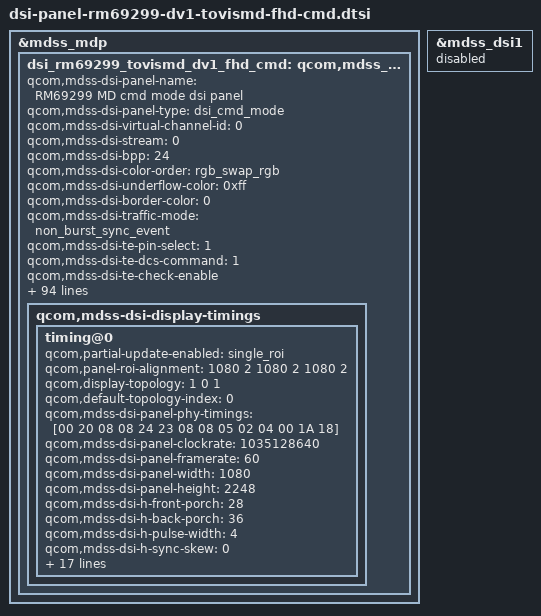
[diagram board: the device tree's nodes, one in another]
/* Copyright (c) 2014, Code Aurora Forum. All rights reserved.
 *
 * This program is free software; you can redistribute it and/or modify
 * it under the terms of the GNU General Public License version 2 and
 * only version 2 as published by the Free Software Foundation.
 *
 * This program is distributed in the hope that it will be useful,
 * but WITHOUT ANY WARRANTY; without even the implied warranty of
 * MERCHANTABILITY or FITNESS FOR A PARTICULAR PURPOSE.  See the
 * GNU General Public License for more details.
 */

&mdss_mdp {
    dsi_rm69299_tovismd_dv1_fhd_cmd: qcom,mdss_dsi_rm69299_tovismd_dv1_fhd_cmd {
		qcom,mdss-dsi-panel-name = "RM69299 MD cmd mode dsi panel";
		qcom,mdss-dsi-panel-type = "dsi_cmd_mode";
		qcom,mdss-dsi-virtual-channel-id = <0>;
		qcom,mdss-dsi-stream = <0>;
		qcom,mdss-dsi-bpp = <24>;
		qcom,mdss-dsi-color-order = "rgb_swap_rgb";
		qcom,mdss-dsi-underflow-color = <0xff>;
		qcom,mdss-dsi-border-color = <0>;
		qcom,mdss-dsi-traffic-mode = "non_burst_sync_event";
		qcom,mdss-dsi-te-pin-select = <1>;
		qcom,mdss-dsi-te-dcs-command = <1>;
		qcom,mdss-dsi-te-check-enable;
		qcom,mdss-dsi-te-using-te-pin;
		qcom,mdss-dsi-lane-map = "lane_map_0123";
		qcom,mdss-dsi-bllp-eof-power-mode;
		qcom,mdss-dsi-bllp-power-mode;
		qcom,mdss-dsi-lane-0-state;
		qcom,mdss-dsi-lane-1-state;
		qcom,mdss-dsi-lane-2-state;
		qcom,mdss-dsi-lane-3-state;
		qcom,mdss-dsi-reset-sequence = <1 10>, <0 2>, <1 10>;
		qcom,mdss-dsi-dma-trigger = "trigger_sw";
		qcom,mdss-dsi-mdp-trigger = "none";
		qcom,mdss-dsi-wr-mem-start = <0x2c>;
		qcom,mdss-dsi-wr-mem-continue = <0x3c>;
		qcom,mdss-dsi-lp11-init;
		qcom,mdss-dsi-tx-eot-append;
		qcom,ulps-enabled;
		qcom,mdss-dsi-panel-hdr-enabled;
		qcom,mdss-dsi-panel-hdr-color-primaries = <14880 15935 32435 16555 14945 30910 7790 3415>;
		qcom,mdss-dsi-panel-peak-brightness = <5643000>;
		qcom,mdss-dsi-panel-blackness-level = <6134>;
		qcom,esd-check-enabled;
		qcom,mdss-dsi-panel-status-check-mode = "te_signal_check";

		lge,blmap = <
			0
			3 3 3 3 3 3 3 3 3 3 3 3 4 4 4 4 4 5 5 5
			5 5 6 6 6 6 6 6 7 7 7 7 7 8 8 8 8 9 9 10
			10 11 11 12 12 13 13 14 14 15 15 16 16 17 17 18 18 19 19 20
			20 21 22 23 24 25 26 26 27 28 29 30 31 32 33 34 35 36 37 37
			38 40 41 43 42 43 45 46 48 49 50 52 53 55 56 57 59 60 61 63
			64 66 67 68 70 71 73 74 76 78 80 82 84 86 88 90 92 94 96 98
			100 102 104 106 108 110 112 114 116 118 120 122 124 126 129 131 134 136 139 141
			144 146 148 151 154 156 159 161 164 166 169 172 174 177 179 182 184 187 190 194
			197 201 204 208 212 215 219 222 226 229 233 237 240 244 247 251 255 258 262 265
			269 272 276 281 285 290 295 299 304 309 313 318 323 327 332 337 341 346 351 355
			360 365 369 374 379 383 388 394 401 407 413 419 426 432 438 445 451 457 463 470
			476 482 488 495 501 507 514 520 526 532 539 545 551 556 562 568 573 579 585 590
			596 602 607 613 618 624 630 635 641 647 652 658 664 669 675 676 676 677 678 679
			679 680 681 682 682 683 684 685 685 686 687 688 688 689 690 691 691 692 693 694
			694 695 696 697 697 698 701 703 706 708 711 713 716 718 722 726 729 733 737 741
			744 748 750 751 753 755 756 758 760 761 763 765 766 768 770 771 773 775 776 778
			782 786 790 795 799 803 807 811 815 820 824 828 832 836 840 844 848 852 856 861
			865 869 873 877 881 885 892 900 907 914 921 929 936 943 950 958 965 972 979 987
			994 1001 1008 1016 1023
			>;
		lge,blmap-ve = <
			0
			3 3 3 3 3 3 3 3 3 3 3 3 4 4 4 4 5 5 5 5
			6 6 6 6 6 7 7 7 7 8 8 8 8 9 9 9 10 11 11 12
			13 14 14 15 16 17 17 18 19 20 20 21 22 23 23 24 25 26 26 27
			28 29 31 32 34 35 37 38 39 41 42 44 45 46 48 49 51 52 54 55
			56 59 61 63 62 64 67 69 71 74 76 78 80 83 85 87 90 92 94 97
			99 101 103 106 108 110 113 115 118 121 124 127 130 133 136 139 142 145 148 151
			155 158 161 164 167 170 173 176 179 182 185 188 191 194 198 203 207 212 216 221
			225 228 233 237 241 246 250 255 259 264 268 273 277 281 286 290 295 299 305 311
			318 324 330 336 343 349 355 361 368 374 380 386 393 399 405 411 418 424 430 436
			443 449 455 462 470 477 485 492 500 507 514 522 529 537 544 551 559 566 574 581
			589 596 603 611 618 626 633 640 647 654 661 668 675 683 690 697 704 711 718 725
			732 739 746 753 760 768 775 782 789 796 803 810 819 829 838 847 856 866 875 884
			893 903 912 921 930 940 949 958 967 977 986 995 1004 1014 1023 1023 1023 1023 1023 1023
			1023 1023 1023 1023 1023 1023 1023 1023 1023 1023 1023 1023 1023 1023 1023 1023 1023 1023 1023 1023
			1023 1023 1023 1023 1023 1023 1023 1023 1023 1023 1023 1023 1023 1023 1023 1023 1023 1023 1023 1023
			1023 1023 1023 1023 1023 1023 1023 1023 1023 1023 1023 1023 1023 1023 1023 1023 1023 1023 1023 1023
			1023 1023 1023 1023 1023 1023 1023 1023 1023 1023 1023 1023 1023 1023 1023 1023 1023 1023 1023 1023
			1023 1023 1023 1023 1023 1023 1023 1023 1023 1023 1023 1023 1023 1023 1023 1023 1023 1023 1023 1023
			1023 1023 1023 1023 1023
			>;
		lge,blmap-ex = <
			0
			1 1 1 1 1 1 1 1 1 1 1 1 1 1 2 2 2 2 2 3
			3 3 3 3 4 4 4 4 4 5 5 5 5 5 5 5 5 6 6 7
			7 8 8 9 9 10 10 11 11 12 12 13 13 14 14 15 15 16 16 17
			17 18 18 19 19 20 20 21 21 22 22 23 23 23 23 23 24 25 26 27
			28 29 30 31 32 33 34 35 36 37 38 39 40 40 40 40 40 40 40 40
			41 42 43 44 45 46 47 48 49 50 51 52 52 52 52 53 53 54 54 55
			55 56 56 57 57 58 58 59 59 60 60 61 61 62 62 62 62 62 62 62
			63 64 65 66 67 68 69 70 71 72 73 74 75 76 77 78 79 80 80 80
			80 80 80 80 80 80 80 80 80 80 80 80 80 80 80 80 80 80 80 80
			80 80 80 80 80 80 80 80 80 80 80 80 80 80 80 80 80 80 80 80
			80 80 80 80 80 80 80 80 80 80 80 80 80 80 80 80 80 80 80 80
			80 80 80 80 80 80 80 80 80 80 80 80 80 80 80 80 80 80 80 80
			80 80 80 80 80 80 80 80 80 80 80 80 80 80 80
		>;
		lge,blmap-hdr = <
			0
			3 3 3 3 3 3 3 3 3 3 3 3 4 4 4 4 5 5 5 5
			6 6 6 6 6 7 7 7 7 8 8 8 8 9 9 9 10 10 11 12
			13 13 14 15 15 16 17 18 18 19 20 21 21 22 23 23 24 25 26 26
			27 28 30 31 33 34 36 37 38 40 41 43 44 45 47 48 50 51 53 54
			55 58 60 62 61 63 66 68 70 72 75 77 79 81 84 86 88 90 93 95
			97 99 102 104 106 108 111 113 116 118 121 124 126 129 132 134 137 140 142 145
			148 150 153 155 158 161 163 166 169 171 174 177 179 182 186 191 195 200 204 209
			213 216 220 225 229 233 238 242 247 251 256 260 265 269 273 278 282 287 293 299
			305 311 317 323 329 334 340 346 352 358 364 370 376 382 388 394 400 405 411 417
			423 429 435 442 450 457 464 471 479 486 493 501 508 515 523 530 537 544 552 559
			566 574 581 588 595 603 610 617 624 630 637 644 651 657 664 671 678 684 691 698
			705 711 718 725 732 738 745 752 759 765 772 779 788 798 807 816 826 835 844 853
			863 872 881 891 900 909 919 928 937 946 956 965 974 984 993 993 993 993 993 993
			993 993 994 994 994 994 994 994 994 994 994 994 994 994 994 994 994 994 995 995
			995 995 995 995 995 995 995 995 995 996 996 996 996 996 996 997 997 997 997 998
			998 998 998 998 998 998 998 998 998 998 999 999 999 999 999 999 999 999 999 999
			999 1000 1000 1001 1001 1001 1002 1002 1002 1003 1003 1004 1004 1005 1005 1006 1007 1007 1008 1009
			1010 1010 1011 1012 1012 1013 1014 1014 1015 1015 1016 1016 1017 1017 1018 1018 1019 1019 1020 1020
			1021 1021 1022 1022 1023
		>;
		qcom,mdss-pan-physical-width-dimension = <68>;
		qcom,mdss-pan-physical-height-dimension = <142>;

		qcom,mdss-dsi-t-clk-post = <0x18>;
		qcom,mdss-dsi-t-clk-pre = <0x1A>;

		lge,use-ambient;
		lge,aod-interface-data = "semi-partial", "semi-partial", "semi-partial";
		lge,mdss-dsi-nolp-command = [
			15 01 00 00 00 00 02 FE 00
			05 01 00 00 20 00 01 28
			15 01 00 00 00 00 02 FE 20
			15 01 00 00 00 00 02 72 11
			15 01 00 00 00 00 02 FE 00
			05 01 00 00 20 00 01 13
			15 01 00 00 00 00 02 FE D0
			15 01 00 00 00 00 02 5C C0
			15 01 00 00 00 00 02 FE 00
			05 01 00 00 00 00 01 38
			15 01 00 00 00 00 02 53 E0
			05 01 00 00 85 00 01 29
		];
		lge,mdss-dsi-nolp-command-state = "dsi_lp_mode";

		lge,mdss-dsi-aod-area-command = [
			15 01 00 00 00 00 02 FE 00
			39 01 00 00 00 00 05 30 00 00 04 37
		];
		lge,mdss-dsi-aod-area-command-state = "dsi_lp_mode";

		lge,mdss-dsi-lp2-command = [
			15 01 00 00 00 00 02 FE 00
			05 01 00 00 00 00 01 28
			15 01 00 00 20 00 02 53 20
			15 01 00 00 00 00 02 FE 20
			15 01 00 00 00 00 02 72 16
			15 01 00 00 00 00 02 FE 00
			05 01 00 00 20 00 01 12
			15 01 00 00 00 00 02 FE D0
			15 01 00 00 00 00 02 5C D0
			15 01 00 00 00 00 02 FE 00
			05 01 00 00 00 00 01 39
			05 01 00 00 85 00 01 29
		];
		lge,mdss-dsi-lp2-command-state = "dsi_lp_mode";

		lge,use-color-manager;
		lge,color-manager-default-status = <1>;
		lge,mdss-dsi-color-manager-mode-table = <0 1>, <1 1>, <2 1>, <3 1>;
		lge,digital-gamma-absent;
		lge,true-view-supported;
		lge,mdss-dsi-disp-ctrl-command-1 = [
			15 01 00 00 00 00 02 FE 00
			15 01 00 00 00 00 02 53 E0
			15 01 00 00 00 00 02 5C 00
			15 01 00 00 00 00 02 FE 80
			15 01 00 00 00 00 02 05 00
			15 01 00 00 00 00 02 FE 12
			15 01 00 00 00 00 02 84 08
			15 01 00 00 00 00 02 FE 00
		];
		lge,mdss-dsi-disp-ctrl-command-1-state = "dsi_lp_mode";
		lge,mdss-dsi-disp-ctrl-command-2 = [
			15 01 00 00 00 00 02 FE 40
			15 01 00 00 00 00 02 79 00
			15 01 00 00 00 00 02 FE 00
		];
		lge,mdss-dsi-disp-ctrl-command-2-state = "dsi_lp_mode";

		lge,color-mode-cmds-dummy = [
			/* CE setting */
			15 00 00 00 00 00 02 FE 00
			15 00 00 00 00 00 02 5A 0B
			/* HUE, SAT enable/disable */
			15 00 00 00 00 00 02 FE 80
			15 00 00 00 00 00 02 00 4F
			/* CE gain */
			15 00 00 00 00 00 02 08 E0
			15 00 00 00 00 00 02 09 00
			15 00 00 00 00 00 02 0A ED
			15 00 00 00 00 00 02 0B 00
			15 00 00 00 00 00 02 0C 00
			15 00 00 00 00 00 02 0D 00
			15 00 00 00 00 00 02 0E CD
			15 00 00 00 00 00 02 0F 0F
			15 00 00 00 00 00 02 14 00
			15 00 00 00 00 00 02 15 A6
			15 00 00 00 00 00 02 16 F5
			15 00 00 00 00 00 02 17 09
			15 00 00 00 00 00 02 18 7E
			15 00 00 00 00 00 02 19 00
			15 00 00 00 00 00 02 1A 68
			15 00 00 00 00 00 02 1B 03
			/* Default CM */
			15 00 00 00 00 00 02 FE 10
			15 00 00 00 00 00 02 00 D9
			15 00 00 00 00 00 02 01 67
			15 00 00 00 00 00 02 02 00
			15 00 00 00 00 00 02 03 21
			15 00 00 00 00 00 02 04 20
			15 00 00 00 00 00 02 05 81
			15 00 00 00 00 00 02 06 FF
			15 00 00 00 00 00 02 07 17
			15 00 00 00 00 00 02 08 80
			15 00 00 00 00 00 02 09 01
			15 00 00 00 00 00 02 0A 80
			15 00 00 00 00 00 02 0B 80
			15 00 00 00 00 00 02 0C FF
			15 00 00 00 00 00 02 0D 07
			15 00 00 00 00 00 02 2F 19
			15 00 00 00 00 00 02 FE D0
			15 00 00 00 00 00 02 80 00
			15 01 00 00 00 00 02 FE 00
		];
		lge,color-mode-cmds-dummy-state = "dsi_lp_mode";

		lge,use-color-manager-lut;
		lge,cm-lut-screen-mode-set-name = "def", "cin", "pho", "web", "spo", "gam", "exp";
		lge,cm-lut-screen-mode-set-cnt = <38>;
		lge,cm-lut-screen-mode-set = [
			00 0B 80 4F E0 00 ED 00 00 00 CD 0F 00 A6 F5 09 7E 00 68 03 10 D9 67 00 21 20 81 FF 17 80 01 80 80 FF 07 19 D0 00 /* def */
			00 0B 80 4F CC 0E ED E0 DF DD 48 00 00 A2 F5 0F FE 02 68 03 10 69 97 06 35 30 00 6B 97 02 01 58 00 F2 06 17 D0 00 /* cin */
			00 0B 80 4F CD 0E EE E0 DE DD 48 00 00 A4 F5 0F FE 02 68 03 10 FF 67 8D 47 E0 06 6E 46 03 38 30 00 44 06 17 D0 00 /* pho */
			00 0B 80 4F CD 0E 0F E0 DE DD 68 00 00 A2 F5 0F FE 02 68 03 10 D6 65 20 41 C0 04 17 07 03 27 40 0B 1E 06 17 D0 00 /* web */
			00 0B 80 4F E0 00 ED 00 00 00 CD 0F 00 A6 F5 09 7E 00 68 03 10 44 07 00 21 00 00 87 97 80 00 08 80 FF 07 17 D0 00 /* spo */
			00 0B 80 4F F1 21 FE 33 22 22 CD 0F 00 A6 F5 09 7E 00 68 03 10 B6 07 00 1F 00 00 D9 97 80 00 00 00 FF 07 17 D0 00 /* gam */
			00 0B 80 4F E0 00 ED 00 00 00 CD 0F 00 A6 F5 09 7E 00 68 03 10 D9 67 00 21 20 81 FF 17 80 01 80 80 FF 07 19 D0 00 /* exp */
		];

		lge,cm-lut-saturation-cnt = <20>;
		lge,cm-lut-saturation = [
			00 0B 80 4F CD CD CC CC CC DC 00 00 00 A6 F5 09 7E 00 68 03
			00 0B 80 4F DF DF ED EE EE EE 00 00 00 A6 F5 09 7E 00 68 03
			00 0B 80 4F E0 00 ED 00 00 00 CD 0F 00 A6 F5 09 7E 00 68 03
			00 0B 80 4F F1 21 FE 33 22 22 CD 0F 00 A6 F5 09 7E 00 68 03
			00 0B 80 4F 13 33 0F 44 55 33 EF 0F 00 A6 F5 09 7E 00 68 03
		];
		lge,cm-lut-rgb-hue-cnt = <18>;
		lge,cm-lut-rgb-hue = [
			10 B7 A5 00 5F 91 08 76 27 00 01 A0 0F 46 06 17 D0 00 /*Hue1 CT1~CT5*/
			10 27 A6 00 5F 91 08 76 27 00 01 A0 0F AC 06 17 D0 00
			10 97 A6 00 5F 91 08 76 27 00 01 A0 0F 06 07 17 D0 00
			10 97 A6 00 5F 91 08 1F 27 00 01 A0 0F F9 06 17 D0 00
			10 97 A6 00 5F 91 08 B6 26 00 01 A0 0F F6 06 17 D0 00
			10 51 86 00 C7 A0 04 B4 27 00 01 18 08 C0 06 17 D0 00 /*Hue2 CT1~CT5*/
			10 D1 86 00 C7 A0 04 B4 27 00 01 18 08 2B 07 17 D0 00
			10 31 87 00 C7 A0 04 B4 27 00 01 18 08 80 07 17 D0 00
			10 31 87 00 C7 A0 04 64 27 00 01 18 08 78 07 17 D0 00
			10 31 87 00 C7 A0 04 00 27 00 01 18 08 70 07 17 D0 00
			10 F1 06 00 1D 00 80 FF 87 80 00 00 00 30 07 17 D0 00 /*Hue3 CT1~CT5*/
			10 67 07 00 1E 00 80 FF 97 80 00 00 00 99 07 17 D0 00
			10 D9 67 00 21 20 81 FF 17 80 01 80 80 FF 07 19 D0 00
			10 E1 07 00 20 00 80 B7 97 80 00 00 00 F5 07 17 D0 00
			10 E1 07 00 21 00 80 4C 97 80 00 00 00 F1 07 17 D0 00
			10 7A 86 0A 02 10 80 94 D7 06 4F 30 00 EA 06 17 D0 00 /*Hue4 CT1~CT5*/
			10 F6 86 0A 02 10 80 94 D7 06 4F 30 00 58 07 17 D0 00
			10 56 87 0A 02 10 80 94 D7 06 4F 30 00 AE 07 17 D0 00
			10 56 87 0A 02 10 80 44 D7 06 4F 30 00 A8 07 17 D0 00
			10 56 87 0A 02 10 80 DB D6 06 4F 30 00 9E 07 17 D0 00
			10 E8 85 13 01 28 80 37 B7 0C 94 40 00 A8 06 17 D0 00 /*Hue5 CT1~CT5*/
			10 60 86 13 01 28 80 37 B7 0C 94 40 00 10 07 17 D0 00
			10 C8 86 13 01 28 80 37 B7 0C 94 40 00 68 07 17 D0 00
			10 C8 86 13 01 28 80 E7 B6 0C 94 40 00 60 07 17 D0 00
			10 C8 86 13 01 28 80 82 B6 0C 94 40 00 5E 07 17 D0 00
		];

		lge,cm-lut-sharpness-cnt = <1>;
		lge,cm-lut-sharpness = [08 12 1C 26 30];

		lge,cm-lut-trueview-cnt = <18>;
		lge,cm-lut-trueview = [
			10 D9 67 00 21 20 81 FF 17 80 01 80 80 FF 07 19 D0 00
			10 74 07 00 20 00 00 A8 A7 80 00 08 00 FF 07 17 D0 00
			10 87 07 00 20 00 80 BB 97 80 00 00 00 FF 07 17 D0 00
			10 9C 07 00 1F 00 80 CB 97 80 00 00 00 FF 07 17 D0 00
			10 B6 07 00 1F 00 00 D9 97 80 00 00 00 FF 07 17 D0 00
			10 C1 07 00 1F 00 80 E5 97 80 00 08 00 FF 07 17 D0 00
			10 D9 67 00 21 20 81 FF 17 80 01 80 80 FF 07 17 D0 00
			10 E2 07 00 1E 00 80 F4 97 80 00 00 00 E0 07 17 D0 00
			10 E3 07 00 1E 00 00 E8 97 80 00 08 00 BB 07 17 D0 00
			10 E3 07 00 1E 00 00 E3 97 80 00 00 00 A6 07 17 D0 00
			10 E3 07 80 1D 00 00 DA 97 80 00 08 00 7D 07 17 D0 00
			10 E4 07 80 1D 00 80 C7 97 80 00 08 80 61 07 17 D0 00
			10 E4 07 00 1D 00 00 C9 97 80 00 08 00 51 07 17 D0 00
			10 E5 07 00 1C 00 80 BA 87 80 00 08 00 33 07 17 D0 00
			10 E5 07 00 1C 00 80 A5 87 80 00 00 00 17 07 17 D0 00
			10 E6 07 00 1C 00 80 94 87 80 00 00 00 EE 06 17 D0 00
			10 E6 07 80 1C 00 80 82 87 80 00 00 00 D5 06 17 D0 00
			10 E7 07 00 1B 00 80 6C 87 80 00 00 00 AA 06 17 D0 00
			10 E7 07 00 1B 00 00 5F 87 80 00 08 00 8D 06 17 D0 00
			10 E7 07 00 1B 00 00 4D 87 80 00 08 00 71 06 17 D0 00
			10 E8 07 00 1A 00 00 3E 87 80 00 08 00 53 06 17 D0 00
			10 E8 07 00 1A 00 00 31 87 80 00 08 00 33 06 17 D0 00
			10 E9 07 00 1A 00 80 22 87 80 00 00 00 19 06 17 D0 00
			10 E9 07 00 19 00 00 1D 87 80 00 08 00 07 06 17 D0 00
			10 EA 07 00 19 00 00 12 77 80 00 08 00 E4 05 17 D0 00
			10 EA 07 00 19 00 80 09 77 80 00 08 00 D6 05 17 D0 00
			10 EA 07 00 19 00 00 FC 76 80 00 08 00 BF 05 17 D0 00
			10 29 97 06 35 30 00 4B 97 02 01 58 00 FC 06 17 D0 00
			10 49 97 06 35 30 00 5B 97 02 01 58 00 F7 06 17 D0 00
			10 69 97 06 35 30 00 6B 97 02 01 58 00 F2 06 17 D0 00
			10 69 97 06 35 30 00 67 97 02 01 58 00 D5 06 17 D0 00
			10 69 97 06 35 30 00 5B 97 02 01 58 00 BD 06 17 D0 00
			10 FA 67 8D 47 E0 06 7E 46 03 38 30 00 70 06 17 D0 00
			10 FB 67 8D 47 E0 06 70 46 03 38 30 00 54 06 17 D0 00
			10 FF 67 8D 47 E0 06 6E 46 03 38 30 00 44 06 17 D0 00
			10 FF 67 8D 47 E0 06 62 46 03 38 30 00 24 06 17 D0 00
			10 FF 67 8D 47 E0 06 59 46 03 38 30 00 0A 06 17 D0 00
			10 96 65 20 41 C0 04 07 07 03 27 40 0B 35 06 17 D0 00
			10 B0 65 20 41 C0 04 10 07 03 27 40 0B 28 06 17 D0 00
			10 D6 65 20 41 C0 04 17 07 03 27 40 0B 1E 06 17 D0 00
			10 D6 65 20 41 C0 04 06 07 03 27 40 0B FB 05 17 D0 00
			10 D6 65 20 41 C0 04 01 07 03 27 40 0B E5 05 17 D0 00
		];

		/* Video Enahnacement */
		lge,mdss-dsi-ve-on-command = [
			15 01 00 00 00 00 02 FE 00
			15 01 00 00 00 00 02 6A A8
		];
		lge,mdss-dsi-ve-on-command-state = "dsi_lp_mode";

		lge,mdss-dsi-ve-off-command = [
			15 01 00 00 00 00 02 FE 00
			15 01 00 00 00 00 02 6A 50
		];
		lge,mdss-dsi-ve-off-command-state = "dsi_lp_mode";

		lge,disp-br-ctrl-ext-supported;
		lge,ddic-dsi-br-ctrl-ext-command = [
			15 01 00 00 00 00 02 FE 70
			15 01 00 00 00 00 02 A9 00
			15 01 00 00 00 00 02 FE 00
		];
		lge,ddic-dsi-br-ctrl-ext-command-state = "dsi_lp_mode";

		qcom,mdss-dsi-display-timings {
			timing@0{
				qcom,partial-update-enabled = "single_roi";
				qcom,panel-roi-alignment = <1080 2 1080 2 1080 2>;
				qcom,display-topology = <1 0 1>;
				qcom,default-topology-index = <0>;
				qcom,mdss-dsi-panel-phy-timings = [00 20 08 08 24 23 08 08 05 02 04 00 1A 18];
				qcom,mdss-dsi-panel-clockrate = <1035128640>;
				qcom,mdss-dsi-panel-framerate = <60>;
				qcom,mdss-dsi-panel-width = <1080>;
				qcom,mdss-dsi-panel-height = <2248>;
				qcom,mdss-dsi-h-front-porch = <28>;
				qcom,mdss-dsi-h-back-porch = <36>;
				qcom,mdss-dsi-h-pulse-width = <4>;
				qcom,mdss-dsi-h-sync-skew = <0>;
				qcom,mdss-dsi-v-back-porch = <4>;
				qcom,mdss-dsi-v-front-porch = <56>;
				qcom,mdss-dsi-v-pulse-width = <4>;
				qcom,mdss-dsi-h-left-border = <0>;
				qcom,mdss-dsi-h-right-border = <0>;
				qcom,mdss-dsi-v-top-border = <0>;
				qcom,mdss-dsi-v-bottom-border = <0>;
				qcom,mdss-mdp-transfer-time-us = <15200>;

				qcom,mdss-dsi-on-command = [
					15 00 00 00 00 00 02 FE 00
					15 00 00 00 00 00 02 5A 0B
					15 01 00 00 00 00 02 5C 00
					15 00 00 00 00 00 02 FE 80
					15 00 00 00 00 00 02 00 4F
					15 00 00 00 00 00 02 08 E0
					15 00 00 00 00 00 02 09 00
					15 00 00 00 00 00 02 0A ED
					15 00 00 00 00 00 02 0B 00
					15 00 00 00 00 00 02 0C 00
					15 00 00 00 00 00 02 0D 00
					15 00 00 00 00 00 02 0E CD
					15 00 00 00 00 00 02 0F 0F
					15 00 00 00 00 00 02 14 00
					15 00 00 00 00 00 02 15 A6
					15 00 00 00 00 00 02 16 F5
					15 00 00 00 00 00 02 17 09
					15 00 00 00 00 00 02 18 7E
					15 00 00 00 00 00 02 19 00
					15 00 00 00 00 00 02 1A 68
					15 01 00 00 00 00 02 1B 03
					15 00 00 00 00 00 02 FE 40
					15 00 00 00 00 00 02 79 10
					15 00 00 00 00 00 02 0E 50
					15 00 00 00 00 00 02 4D 77
					15 00 00 00 00 00 02 6E D0
					15 00 00 00 00 00 02 6F 00
					15 00 00 00 00 00 02 0D 98
					15 00 00 00 00 00 02 2D 29
					15 00 00 00 00 00 02 30 32
					15 01 00 00 00 00 02 64 02
					15 00 00 00 00 00 02 FE 70
					15 01 00 00 00 00 02 CB 05
					15 00 00 00 00 00 02 FE D0
					15 01 00 00 00 00 02 43 C0
					15 00 00 00 00 00 02 FE 00
					15 01 00 00 00 00 02 C2 08
					05 01 00 00 00 00 01 35
					15 01 00 00 00 00 02 53 E0
					39 01 00 00 00 00 03 51 00 00
					05 01 00 00 78 00 01 11
				];
				qcom,mdss-dsi-on-command-state = "dsi_lp_mode";

				qcom,mdss-dsi-post-panel-on-command = [
					05 01 00 00 20 00 01 29
				];

				qcom,mdss-dsi-off-command = [
					05 01 00 00 00 00 01 28
					05 01 00 00 96 00 01 10
				];
				qcom,mdss-dsi-off-command-state = "dsi_lp_mode";
				qcom,mdss-dsi-h-sync-pulse = <0>;
			};
		};
	};
};
/*
&spmi_bus {
	qcom,pmi8998@3 {
		labibb: qpnp-labibb-regulator {
			status = "disabled";
		};
	};
};
*/
&mdss_dsi1 {
	status = "disabled";
};
